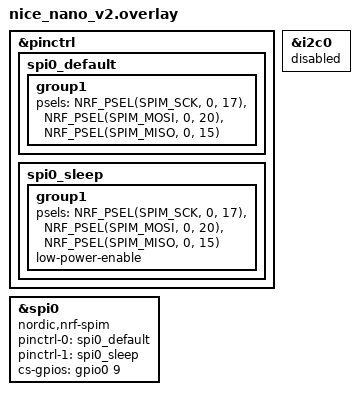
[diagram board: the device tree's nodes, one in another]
/*
 * Copyright (c) 2023 The ZMK Contributors
 *
 * SPDX-License-Identifier: MIT
 */

&pinctrl {
    spi0_default: spi0_default {
        group1 {
            psels = <NRF_PSEL(SPIM_SCK, 0, 17)>,    /* Pro Micro Pin 1 (SCK) */
                    <NRF_PSEL(SPIM_MOSI, 0, 20)>,   /* Pro Micro Pin 0 (MOSI) */
                    <NRF_PSEL(SPIM_MISO, 0, 15)>;   /* Pro Micro Pin 2 (MISO - not used but required by driver) */
        };
    };
    spi0_sleep: spi0_sleep {
        group1 {
            psels = <NRF_PSEL(SPIM_SCK, 0, 17)>,
                    <NRF_PSEL(SPIM_MOSI, 0, 20)>,
                    <NRF_PSEL(SPIM_MISO, 0, 15)>;
            low-power-enable;
        };
    };
};

nice_view_spi: &spi0 {
    compatible = "nordic,nrf-spim";
    pinctrl-0 = <&spi0_default>;
    pinctrl-1 = <&spi0_sleep>;
    pinctrl-names = "default", "sleep";
    cs-gpios   = <&gpio0 9 GPIO_ACTIVE_HIGH>;      /* CS – P0.09 / D10 */
};

/* disable on-board I²C so it doesn’t steal our pins (optional)    */
&i2c0 { status = "disabled"; };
